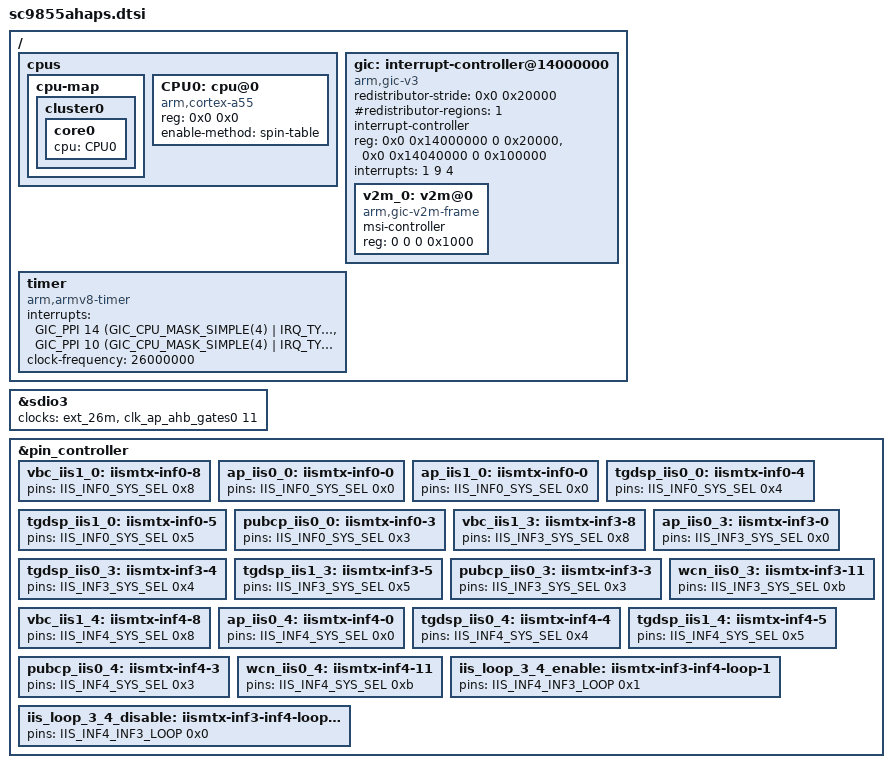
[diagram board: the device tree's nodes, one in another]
/*
 * Spreadtrum SC9855AHaps SoC DTS file
 *
 * Copyright (C) 2017, Spreadtrum Communications Inc.
 *
 * This file is licensed under a dual GPLv2 or X11 license.
 */

#include <dt-bindings/pinctrl/sc9863_pinctrl.h>
#include "sharkl3.dtsi"
#include "sc9855a-clocks.dtsi"

/ {
	cpus {
		#address-cells = <2>;
		#size-cells = <0>;

		cpu-map {
			cluster0 {
				core0 {
					cpu = <&CPU0>;
				};
			};
		};

		CPU0: cpu@0 {
			device_type = "cpu";
			compatible = "arm,cortex-a55","arm,armv8";
			reg = <0x0 0x0>;
			enable-method = "spin-table";
		};

	};

	gic: interrupt-controller@14000000 {
		compatible = "arm,gic-v3";
		#interrupt-cells = <3>;
		#address-cells = <2>;
		#size-cells = <2>;
		ranges;
		redistributor-stride = <0x0 0x20000>;	// 128KB stride
		#redistributor-regions = <1>;
		interrupt-controller;
		reg = <0x0 0x14000000 0 0x20000>,	// GICD
			<0x0 0x14040000 0 0x100000>;	// GICR
		interrupts = <1 9 4>;
		v2m_0: v2m@0 {
			compatible = "arm,gic-v2m-frame";
			msi-controller;
			reg = <0 0 0 0x1000>;
		};
	};

	timer {
		compatible = "arm,armv8-timer";
		interrupts = <GIC_PPI 14 (GIC_CPU_MASK_SIMPLE(4)
					 | IRQ_TYPE_LEVEL_LOW)>,
			     <GIC_PPI 10 (GIC_CPU_MASK_SIMPLE(4)
					 | IRQ_TYPE_LEVEL_LOW)>;
		clock-frequency = <26000000>;
	};
};

&sdio3 {
	clock-names = "sdio_clk_source",
		"sdio_ahb_enable";
	clocks = <&ext_26m>,<&clk_ap_ahb_gates0 11>;
};

&pin_controller {
	vbc_iis1_0: iismtx-inf0-8 {
		pins = <IIS_INF0_SYS_SEL 0x8>;
	};
	ap_iis0_0: iismtx-inf0-0 {
		pins = <IIS_INF0_SYS_SEL 0x0>;
	};
	ap_iis1_0: iismtx-inf0-0 {
		pins = <IIS_INF0_SYS_SEL 0x0>;
	};
	tgdsp_iis0_0: iismtx-inf0-4 {
		pins = <IIS_INF0_SYS_SEL 0x4>;
	};
	tgdsp_iis1_0: iismtx-inf0-5 {
		pins = <IIS_INF0_SYS_SEL 0x5>;
	};
	pubcp_iis0_0: iismtx-inf0-3 {
		pins = <IIS_INF0_SYS_SEL 0x3>;
	};
	vbc_iis1_3: iismtx-inf3-8 {
		pins = <IIS_INF3_SYS_SEL 0x8>;
	};
	ap_iis0_3: iismtx-inf3-0 {
		pins = <IIS_INF3_SYS_SEL 0x0>;
	};
	tgdsp_iis0_3: iismtx-inf3-4 {
		pins = <IIS_INF3_SYS_SEL 0x4>;
	};
	tgdsp_iis1_3: iismtx-inf3-5 {
		pins = <IIS_INF3_SYS_SEL 0x5>;
	};
	pubcp_iis0_3: iismtx-inf3-3 {
		pins = <IIS_INF3_SYS_SEL 0x3>;
	};
	wcn_iis0_3: iismtx-inf3-11 {
		pins = <IIS_INF3_SYS_SEL 0xb>;
	};
	vbc_iis1_4: iismtx-inf4-8 {
		pins = <IIS_INF4_SYS_SEL 0x8>;
	};
	ap_iis0_4: iismtx-inf4-0 {
		pins = <IIS_INF4_SYS_SEL 0x0>;
	};
	tgdsp_iis0_4: iismtx-inf4-4 {
		pins = <IIS_INF4_SYS_SEL 0x4>;
	};
	tgdsp_iis1_4: iismtx-inf4-5 {
		pins = <IIS_INF4_SYS_SEL 0x5>;
	};
	pubcp_iis0_4: iismtx-inf4-3 {
		pins = <IIS_INF4_SYS_SEL 0x3>;
	};
	wcn_iis0_4: iismtx-inf4-11 {
		pins = <IIS_INF4_SYS_SEL 0xb>;
	};
	iis_loop_3_4_enable: iismtx-inf3-inf4-loop-1 {
		pins = <IIS_INF4_INF3_LOOP 0x1>;
	};
	iis_loop_3_4_disable: iismtx-inf3-inf4-loop-0 {
		pins = <IIS_INF4_INF3_LOOP 0x0>;
	};
};
